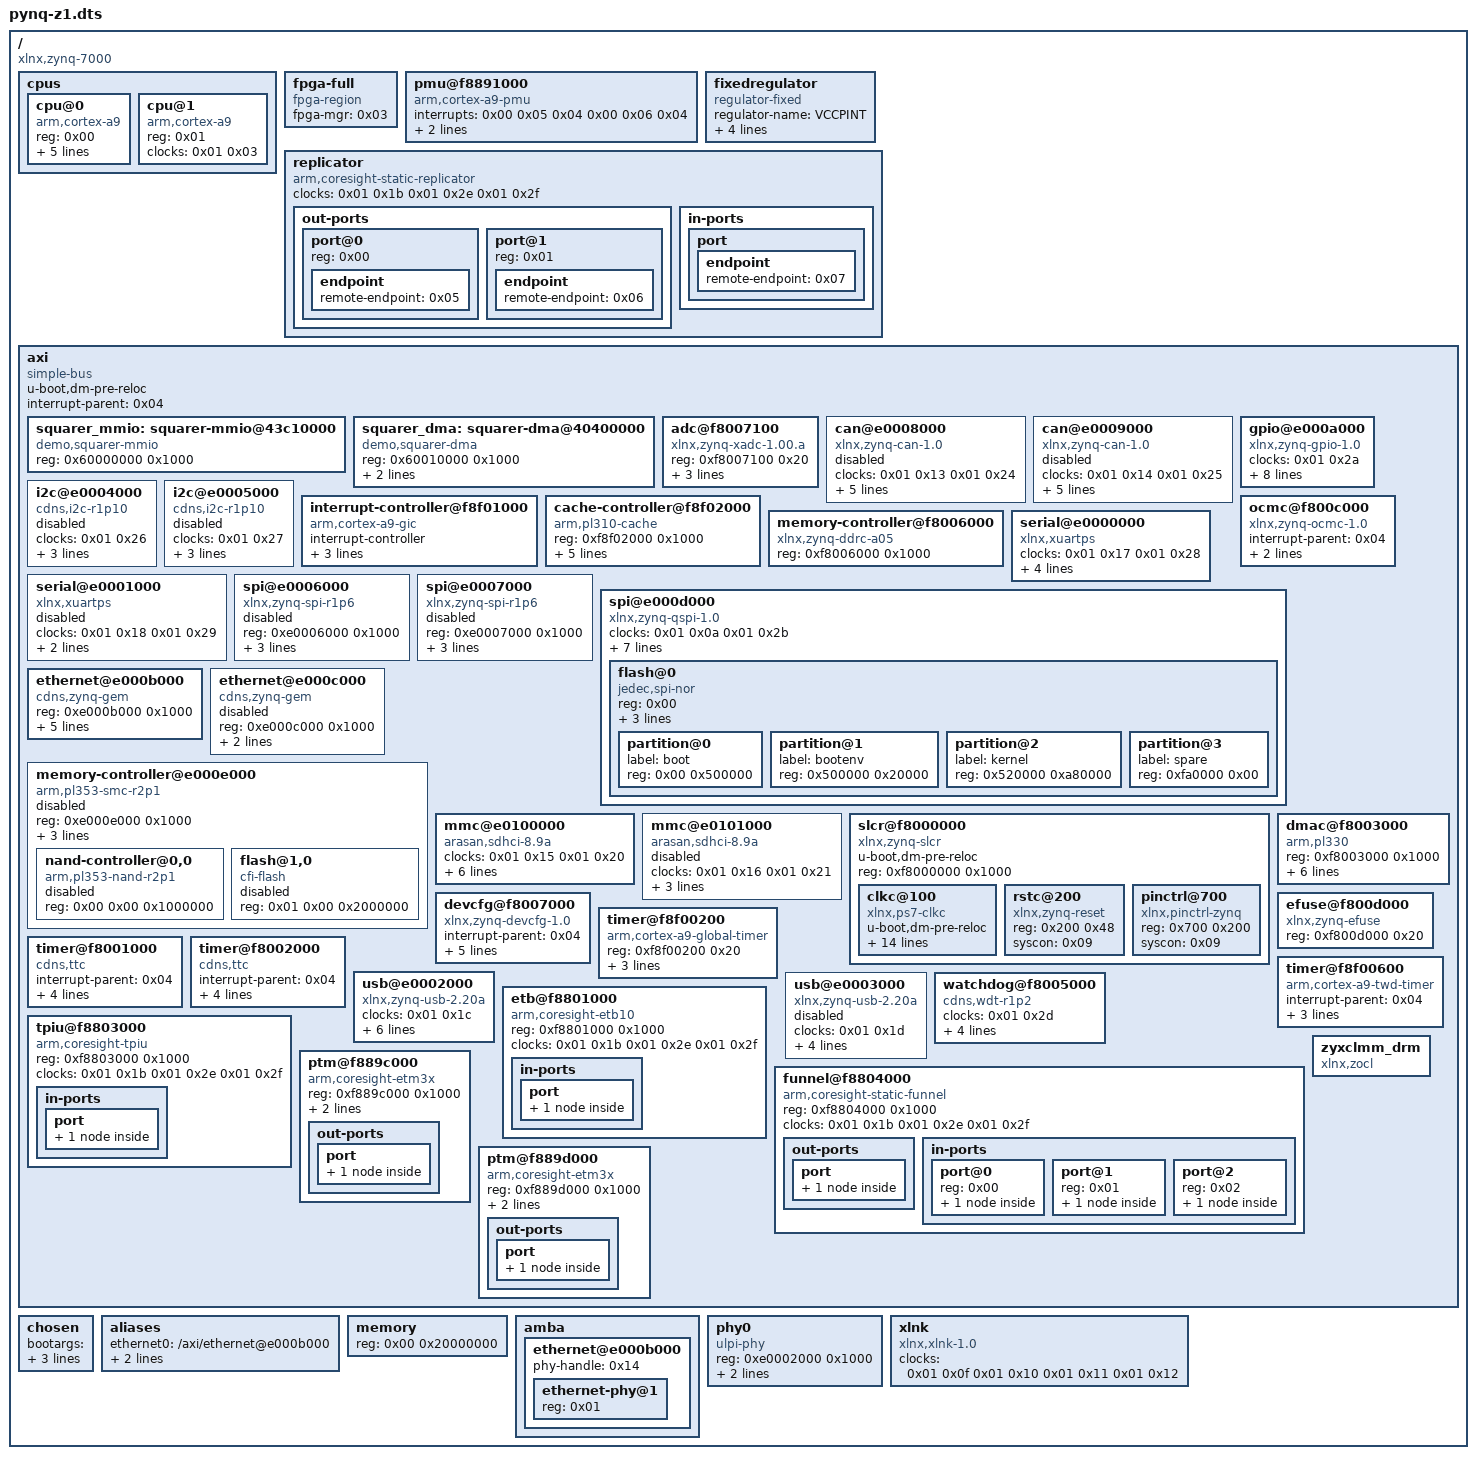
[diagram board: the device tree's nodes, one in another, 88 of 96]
/dts-v1/;

/ {
	#address-cells = <0x01>;
	#size-cells = <0x01>;
	compatible = "xlnx,zynq-7000";

	cpus {
		#address-cells = <0x01>;
		#size-cells = <0x00>;

		cpu@0 {
			compatible = "arm,cortex-a9";
			device_type = "cpu";
			reg = <0x00>;
			clocks = <0x01 0x03>;
			clock-latency = <0x3e8>;
			cpu0-supply = <0x02>;
			operating-points = <0x9eb10 0xf4240 0x4f588 0xf4240>;
			phandle = <0x10>;
		};

		cpu@1 {
			compatible = "arm,cortex-a9";
			device_type = "cpu";
			reg = <0x01>;
			clocks = <0x01 0x03>;
			phandle = <0x12>;
		};
	};

	fpga-full {
		compatible = "fpga-region";
		fpga-mgr = <0x03>;
		#address-cells = <0x01>;
		#size-cells = <0x01>;
		ranges;
		phandle = <0x15>;
	};

	pmu@f8891000 {
		compatible = "arm,cortex-a9-pmu";
		interrupts = <0x00 0x05 0x04 0x00 0x06 0x04>;
		interrupt-parent = <0x04>;
		reg = <0xf8891000 0x1000 0xf8893000 0x1000>;
	};

	fixedregulator {
		compatible = "regulator-fixed";
		regulator-name = "VCCPINT";
		regulator-min-microvolt = <0xf4240>;
		regulator-max-microvolt = <0xf4240>;
		regulator-boot-on;
		regulator-always-on;
		phandle = <0x02>;
	};

	replicator {
		compatible = "arm,coresight-static-replicator";
		clocks = <0x01 0x1b 0x01 0x2e 0x01 0x2f>;
		clock-names = "apb_pclk", "dbg_trc", "dbg_apb";

		out-ports {
			#address-cells = <0x01>;
			#size-cells = <0x00>;

			port@0 {
				reg = <0x00>;

				endpoint {
					remote-endpoint = <0x05>;
					phandle = <0x0c>;
				};
			};

			port@1 {
				reg = <0x01>;

				endpoint {
					remote-endpoint = <0x06>;
					phandle = <0x0b>;
				};
			};
		};

		in-ports {

			port {

				endpoint {
					remote-endpoint = <0x07>;
					phandle = <0x0d>;
				};
			};
		};
	};

	axi {
		u-boot,dm-pre-reloc;
		compatible = "simple-bus";
		#address-cells = <0x01>;
		#size-cells = <0x01>;
		interrupt-parent = <0x04>;
		ranges;
		phandle = <0x16>;

//        smarttimer0: smart-timer@70000000 {
//            compatible = "acme,smarttimer-v1";
//            reg = <0x70000000 0x10000>;
//            interrupts = <0 29 4>; // SPI 29 (on IRQ_F2P[0] of Zynq), level high
//            interrupt-parent = <0x04>;
//            status = "okay";
//        };

        // FIR filter with AXI DMA
        // reg[0] = FIR config registers (AXI-Lite)
        // reg[1] = AXI DMA registers
        // interrupts = S2MM completion IRQ
//        fir0: fir-filter@43c00000 {
//            compatible = "acme,fir-dma-v1";
//            reg = <0x43c00000 0x10000>,   // FIR config @ 0x43C0_0000
//                  <0x40400000 0x10000>;   // AXI DMA   @ 0x4040_0000
//            reg-names = "fir", "dma";
//            interrupts = <0 30 4>;        // SPI 30 (IRQ_F2P[1]), level high
//            interrupt-parent = <0x04>;
//            status = "disabled";          // Disable when using squarer demo
//        };

        // Squarer MMIO demo (slow path - per-sample register access)
        squarer_mmio: squarer-mmio@43c10000 {
            compatible = "demo,squarer-mmio";
            reg = <0x60000000 0x1000>;    // Squarer MMIO @ 0x6000_0000
            status = "okay";
        };

        // Squarer DMA demo (fast path - bulk transfer)
        // Uses AXI DMA for high-throughput data movement
        squarer_dma: squarer-dma@40400000 {
            compatible = "demo,squarer-dma";
            reg = <0x60010000 0x1000>;   // AXI DMA @ 0x6001_0000
            interrupts = <0 29 4>;        // SPI 29 (IRQ_F2P[0]), level high
            interrupt-parent = <0x04>;
            status = "okay";
        };

		adc@f8007100 {
			compatible = "xlnx,zynq-xadc-1.00.a";
			reg = <0xf8007100 0x20>;
			interrupts = <0x00 0x07 0x04>;
			interrupt-parent = <0x04>;
			clocks = <0x01 0x0c>;
			phandle = <0x17>;
		};

		can@e0008000 {
			compatible = "xlnx,zynq-can-1.0";
			status = "disabled";
			clocks = <0x01 0x13 0x01 0x24>;
			clock-names = "can_clk", "pclk";
			reg = <0xe0008000 0x1000>;
			interrupts = <0x00 0x1c 0x04>;
			interrupt-parent = <0x04>;
			tx-fifo-depth = <0x40>;
			rx-fifo-depth = <0x40>;
			phandle = <0x18>;
		};

		can@e0009000 {
			compatible = "xlnx,zynq-can-1.0";
			status = "disabled";
			clocks = <0x01 0x14 0x01 0x25>;
			clock-names = "can_clk", "pclk";
			reg = <0xe0009000 0x1000>;
			interrupts = <0x00 0x33 0x04>;
			interrupt-parent = <0x04>;
			tx-fifo-depth = <0x40>;
			rx-fifo-depth = <0x40>;
			phandle = <0x19>;
		};

		gpio@e000a000 {
			compatible = "xlnx,zynq-gpio-1.0";
			#gpio-cells = <0x02>;
			clocks = <0x01 0x2a>;
			gpio-controller;
			interrupt-controller;
			#interrupt-cells = <0x02>;
			interrupt-parent = <0x04>;
			interrupts = <0x00 0x14 0x04>;
			reg = <0xe000a000 0x1000>;
			emio-gpio-width = <0x40>;
			gpio-mask-high = <0x00>;
			gpio-mask-low = <0x5600>;
			phandle = <0x08>;
		};

		i2c@e0004000 {
			compatible = "cdns,i2c-r1p10";
			status = "disabled";
			clocks = <0x01 0x26>;
			interrupt-parent = <0x04>;
			interrupts = <0x00 0x19 0x04>;
			reg = <0xe0004000 0x1000>;
			#address-cells = <0x01>;
			#size-cells = <0x00>;
			phandle = <0x1a>;
		};

		i2c@e0005000 {
			compatible = "cdns,i2c-r1p10";
			status = "disabled";
			clocks = <0x01 0x27>;
			interrupt-parent = <0x04>;
			interrupts = <0x00 0x30 0x04>;
			reg = <0xe0005000 0x1000>;
			#address-cells = <0x01>;
			#size-cells = <0x00>;
			phandle = <0x1b>;
		};

		interrupt-controller@f8f01000 {
			compatible = "arm,cortex-a9-gic";
			#interrupt-cells = <0x03>;
			interrupt-controller;
			reg = <0xf8f01000 0x1000 0xf8f00100 0x100>;
			num_cpus = <0x02>;
			num_interrupts = <0x60>;
			phandle = <0x04>;
		};

		cache-controller@f8f02000 {
			compatible = "arm,pl310-cache";
			reg = <0xf8f02000 0x1000>;
			interrupts = <0x00 0x02 0x04>;
			arm,data-latency = <0x03 0x02 0x02>;
			arm,tag-latency = <0x02 0x02 0x02>;
			cache-unified;
			cache-level = <0x02>;
			phandle = <0x1c>;
		};

		memory-controller@f8006000 {
			compatible = "xlnx,zynq-ddrc-a05";
			reg = <0xf8006000 0x1000>;
			phandle = <0x1d>;
		};

		ocmc@f800c000 {
			compatible = "xlnx,zynq-ocmc-1.0";
			interrupt-parent = <0x04>;
			interrupts = <0x00 0x03 0x04>;
			reg = <0xf800c000 0x1000>;
			phandle = <0x1e>;
		};

		serial@e0000000 {
			compatible = "xlnx,xuartps", "cdns,uart-r1p8";
			status = "okay";
			clocks = <0x01 0x17 0x01 0x28>;
			clock-names = "uart_clk", "pclk";
			reg = <0xe0000000 0x1000>;
			interrupts = <0x00 0x1b 0x04>;
			cts-override;
			device_type = "serial";
			port-number = <0x00>;
			phandle = <0x1f>;
		};

		serial@e0001000 {
			compatible = "xlnx,xuartps", "cdns,uart-r1p8";
			status = "disabled";
			clocks = <0x01 0x18 0x01 0x29>;
			clock-names = "uart_clk", "pclk";
			reg = <0xe0001000 0x1000>;
			interrupts = <0x00 0x32 0x04>;
			phandle = <0x20>;
		};

		spi@e0006000 {
			compatible = "xlnx,zynq-spi-r1p6";
			reg = <0xe0006000 0x1000>;
			status = "disabled";
			interrupt-parent = <0x04>;
			interrupts = <0x00 0x1a 0x04>;
			clocks = <0x01 0x19 0x01 0x22>;
			clock-names = "ref_clk", "pclk";
			#address-cells = <0x01>;
			#size-cells = <0x00>;
			phandle = <0x21>;
		};

		spi@e0007000 {
			compatible = "xlnx,zynq-spi-r1p6";
			reg = <0xe0007000 0x1000>;
			status = "disabled";
			interrupt-parent = <0x04>;
			interrupts = <0x00 0x31 0x04>;
			clocks = <0x01 0x1a 0x01 0x23>;
			clock-names = "ref_clk", "pclk";
			#address-cells = <0x01>;
			#size-cells = <0x00>;
			phandle = <0x22>;
		};

		spi@e000d000 {
			clock-names = "ref_clk", "pclk";
			clocks = <0x01 0x0a 0x01 0x2b>;
			compatible = "xlnx,zynq-qspi-1.0";
			status = "okay";
			interrupt-parent = <0x04>;
			interrupts = <0x00 0x13 0x04>;
			reg = <0xe000d000 0x1000>;
			#address-cells = <0x01>;
			#size-cells = <0x00>;
			is-dual = <0x00>;
			num-cs = <0x01>;
			spi-rx-bus-width = <0x04>;
			spi-tx-bus-width = <0x04>;
			phandle = <0x23>;

			flash@0 {
				compatible = "jedec,spi-nor";
				reg = <0x00>;
				spi-tx-bus-width = <0x01>;
				spi-rx-bus-width = <0x04>;
				spi-max-frequency = <0x5f5e100>;
				phandle = <0x24>;

				partition@0 {
					label = "boot";
					reg = <0x00 0x500000>;
				};

				partition@1 {
					label = "bootenv";
					reg = <0x500000 0x20000>;
				};

				partition@2 {
					label = "kernel";
					reg = <0x520000 0xa80000>;
				};

				partition@3 {
					label = "spare";
					reg = <0xfa0000 0x00>;
				};
			};
		};

		ethernet@e000b000 {
			compatible = "cdns,zynq-gem", "cdns,gem";
			reg = <0xe000b000 0x1000>;
			status = "okay";
			interrupts = <0x00 0x16 0x04>;
			clocks = <0x01 0x1e 0x01 0x1e 0x01 0x0d>;
			clock-names = "pclk", "hclk", "tx_clk";
			#address-cells = <0x01>;
			#size-cells = <0x00>;
			enet-reset = <0x08 0x09 0x00>;
			phy-mode = "rgmii-id";
			xlnx,ptp-enet-clock = <0x6750918>;
			phandle = <0x25>;
		};

		ethernet@e000c000 {
			compatible = "cdns,zynq-gem", "cdns,gem";
			reg = <0xe000c000 0x1000>;
			status = "disabled";
			interrupts = <0x00 0x2d 0x04>;
			clocks = <0x01 0x1f 0x01 0x1f 0x01 0x0e>;
			clock-names = "pclk", "hclk", "tx_clk";
			#address-cells = <0x01>;
			#size-cells = <0x00>;
			phandle = <0x26>;
		};

		memory-controller@e000e000 {
			compatible = "arm,pl353-smc-r2p1", "arm,primecell";
			reg = <0xe000e000 0x1000>;
			status = "disabled";
			clock-names = "memclk", "apb_pclk";
			clocks = <0x01 0x0b 0x01 0x2c>;
			ranges = <0x00 0x00 0xe1000000 0x1000000 0x01 0x00 0xe2000000 0x2000000 0x02 0x00 0xe4000000 0x2000000>;
			#address-cells = <0x02>;
			#size-cells = <0x01>;
			interrupt-parent = <0x04>;
			interrupts = <0x00 0x12 0x04>;
			phandle = <0x27>;

			nand-controller@0,0 {
				compatible = "arm,pl353-nand-r2p1";
				reg = <0x00 0x00 0x1000000>;
				status = "disabled";
				#address-cells = <0x01>;
				#size-cells = <0x00>;
				phandle = <0x28>;
			};

			flash@1,0 {
				status = "disabled";
				compatible = "cfi-flash";
				reg = <0x01 0x00 0x2000000>;
				#address-cells = <0x01>;
				#size-cells = <0x01>;
				phandle = <0x29>;
			};
		};

		mmc@e0100000 {
			compatible = "arasan,sdhci-8.9a";
			status = "okay";
			clock-names = "clk_xin", "clk_ahb";
			clocks = <0x01 0x15 0x01 0x20>;
			interrupt-parent = <0x04>;
			interrupts = <0x00 0x18 0x04>;
			reg = <0xe0100000 0x1000>;
			xlnx,has-cd = <0x01>;
			xlnx,has-power = <0x00>;
			xlnx,has-wp = <0x00>;
			phandle = <0x2a>;
		};

		mmc@e0101000 {
			compatible = "arasan,sdhci-8.9a";
			status = "disabled";
			clock-names = "clk_xin", "clk_ahb";
			clocks = <0x01 0x16 0x01 0x21>;
			interrupt-parent = <0x04>;
			interrupts = <0x00 0x2f 0x04>;
			reg = <0xe0101000 0x1000>;
			phandle = <0x2b>;
		};

		slcr@f8000000 {
			u-boot,dm-pre-reloc;
			#address-cells = <0x01>;
			#size-cells = <0x01>;
			compatible = "xlnx,zynq-slcr", "syscon", "simple-mfd";
			reg = <0xf8000000 0x1000>;
			ranges;
			phandle = <0x09>;

			clkc@100 {
				u-boot,dm-pre-reloc;
				#clock-cells = <0x01>;
				compatible = "xlnx,ps7-clkc";
				fclk-enable = <0x0f>;
				clock-output-names = "armpll", "ddrpll", "iopll", "cpu_6or4x", "cpu_3or2x", "cpu_2x", "cpu_1x", "ddr2x", "ddr3x", "dci", "lqspi", "smc", "pcap", "gem0", "gem1", "fclk0", "fclk1", "fclk2", "fclk3", "can0", "can1", "sdio0", "sdio1", "uart0", "uart1", "spi0", "spi1", "dma", "usb0_aper", "usb1_aper", "gem0_aper", "gem1_aper", "sdio0_aper", "sdio1_aper", "spi0_aper", "spi1_aper", "can0_aper", "can1_aper", "i2c0_aper", "i2c1_aper", "uart0_aper", "uart1_aper", "gpio_aper", "lqspi_aper", "smc_aper", "swdt", "dbg_trc", "dbg_apb";
				reg = <0x100 0x100>;
				ps-clk-frequency = <0x2faf080>;
				phandle = <0x01>;
			};

			rstc@200 {
				compatible = "xlnx,zynq-reset";
				reg = <0x200 0x48>;
				#reset-cells = <0x01>;
				syscon = <0x09>;
				phandle = <0x2c>;
			};

			pinctrl@700 {
				compatible = "xlnx,pinctrl-zynq";
				reg = <0x700 0x200>;
				syscon = <0x09>;
				phandle = <0x2d>;
			};
		};

		dmac@f8003000 {
			compatible = "arm,pl330", "arm,primecell";
			reg = <0xf8003000 0x1000>;
			interrupt-parent = <0x04>;
			interrupt-names = "abort", "dma0", "dma1", "dma2", "dma3", "dma4", "dma5", "dma6", "dma7";
			interrupts = <0x00 0x0d 0x04 0x00 0x0e 0x04 0x00 0x0f 0x04 0x00 0x10 0x04 0x00 0x11 0x04 0x00 0x28 0x04 0x00 0x29 0x04 0x00 0x2a 0x04 0x00 0x2b 0x04>;
			#dma-cells = <0x01>;
			#dma-channels = <0x08>;
			#dma-requests = <0x04>;
			clocks = <0x01 0x1b>;
			clock-names = "apb_pclk";
			phandle = <0x2e>;
		};

		devcfg@f8007000 {
			compatible = "xlnx,zynq-devcfg-1.0";
			interrupt-parent = <0x04>;
			interrupts = <0x00 0x08 0x04>;
			reg = <0xf8007000 0x100>;
			clocks = <0x01 0x0c 0x01 0x0f 0x01 0x10 0x01 0x11 0x01 0x12>;
			clock-names = "ref_clk", "fclk0", "fclk1", "fclk2", "fclk3";
			syscon = <0x09>;
			phandle = <0x03>;
		};

		efuse@f800d000 {
			compatible = "xlnx,zynq-efuse";
			reg = <0xf800d000 0x20>;
			phandle = <0x2f>;
		};

		timer@f8f00200 {
			compatible = "arm,cortex-a9-global-timer";
			reg = <0xf8f00200 0x20>;
			interrupts = <0x01 0x0b 0x301>;
			interrupt-parent = <0x04>;
			clocks = <0x01 0x04>;
			phandle = <0x30>;
		};

		timer@f8001000 {
			interrupt-parent = <0x04>;
			interrupts = <0x00 0x0a 0x04 0x00 0x0b 0x04 0x00 0x0c 0x04>;
			compatible = "cdns,ttc";
			clocks = <0x01 0x06>;
			reg = <0xf8001000 0x1000>;
			phandle = <0x31>;
		};

		timer@f8002000 {
			interrupt-parent = <0x04>;
			interrupts = <0x00 0x25 0x04 0x00 0x26 0x04 0x00 0x27 0x04>;
			compatible = "cdns,ttc";
			clocks = <0x01 0x06>;
			reg = <0xf8002000 0x1000>;
			phandle = <0x32>;
		};

		timer@f8f00600 {
			interrupt-parent = <0x04>;
			interrupts = <0x01 0x0d 0x301>;
			compatible = "arm,cortex-a9-twd-timer";
			reg = <0xf8f00600 0x20>;
			clocks = <0x01 0x04>;
			phandle = <0x33>;
		};

		usb@e0002000 {
			compatible = "xlnx,zynq-usb-2.20a", "chipidea,usb2";
			status = "okay";
			clocks = <0x01 0x1c>;
			interrupt-parent = <0x04>;
			interrupts = <0x00 0x15 0x04>;
			reg = <0xe0002000 0x1000>;
			phy_type = "ulpi";
			usb-reset = <0x08 0x2e 0x00>;
			usb-phy = <0x0a>;
			phandle = <0x34>;
		};

		usb@e0003000 {
			compatible = "xlnx,zynq-usb-2.20a", "chipidea,usb2";
			status = "disabled";
			clocks = <0x01 0x1d>;
			interrupt-parent = <0x04>;
			interrupts = <0x00 0x2c 0x04>;
			reg = <0xe0003000 0x1000>;
			phy_type = "ulpi";
			phandle = <0x35>;
		};

		watchdog@f8005000 {
			clocks = <0x01 0x2d>;
			compatible = "cdns,wdt-r1p2";
			interrupt-parent = <0x04>;
			interrupts = <0x00 0x09 0x01>;
			reg = <0xf8005000 0x1000>;
			timeout-sec = <0x0a>;
			phandle = <0x36>;
		};

		etb@f8801000 {
			compatible = "arm,coresight-etb10", "arm,primecell";
			reg = <0xf8801000 0x1000>;
			clocks = <0x01 0x1b 0x01 0x2e 0x01 0x2f>;
			clock-names = "apb_pclk", "dbg_trc", "dbg_apb";

			in-ports {

				port {

					endpoint {
						remote-endpoint = <0x0b>;
						phandle = <0x06>;
					};
				};
			};
		};

		tpiu@f8803000 {
			compatible = "arm,coresight-tpiu", "arm,primecell";
			reg = <0xf8803000 0x1000>;
			clocks = <0x01 0x1b 0x01 0x2e 0x01 0x2f>;
			clock-names = "apb_pclk", "dbg_trc", "dbg_apb";

			in-ports {

				port {

					endpoint {
						remote-endpoint = <0x0c>;
						phandle = <0x05>;
					};
				};
			};
		};

		funnel@f8804000 {
			compatible = "arm,coresight-static-funnel", "arm,primecell";
			reg = <0xf8804000 0x1000>;
			clocks = <0x01 0x1b 0x01 0x2e 0x01 0x2f>;
			clock-names = "apb_pclk", "dbg_trc", "dbg_apb";

			out-ports {

				port {

					endpoint {
						remote-endpoint = <0x0d>;
						phandle = <0x07>;
					};
				};
			};

			in-ports {
				#address-cells = <0x01>;
				#size-cells = <0x00>;

				port@0 {
					reg = <0x00>;

					endpoint {
						remote-endpoint = <0x0e>;
						phandle = <0x11>;
					};
				};

				port@1 {
					reg = <0x01>;

					endpoint {
						remote-endpoint = <0x0f>;
						phandle = <0x13>;
					};
				};

				port@2 {
					reg = <0x02>;

					endpoint {
						phandle = <0x37>;
					};
				};
			};
		};

		ptm@f889c000 {
			compatible = "arm,coresight-etm3x", "arm,primecell";
			reg = <0xf889c000 0x1000>;
			clocks = <0x01 0x1b 0x01 0x2e 0x01 0x2f>;
			clock-names = "apb_pclk", "dbg_trc", "dbg_apb";
			cpu = <0x10>;

			out-ports {

				port {

					endpoint {
						remote-endpoint = <0x11>;
						phandle = <0x0e>;
					};
				};
			};
		};

		ptm@f889d000 {
			compatible = "arm,coresight-etm3x", "arm,primecell";
			reg = <0xf889d000 0x1000>;
			clocks = <0x01 0x1b 0x01 0x2e 0x01 0x2f>;
			clock-names = "apb_pclk", "dbg_trc", "dbg_apb";
			cpu = <0x12>;

			out-ports {

				port {

					endpoint {
						remote-endpoint = <0x13>;
						phandle = <0x0f>;
					};
				};
			};
		};

		zyxclmm_drm {
			compatible = "xlnx,zocl";
			status = "okay";
		};
	};

	chosen {
		bootargs = "root=/dev/mmcblk0p2 rw earlyprintk rootfstype=ext4 rootwait devtmpfs.mount=1 uio_pdrv_genirq.of_id=\"generic-uio\" clk_ignore_unused";
		stdout-path = "serial0:115200n8";
		pynq_board = "Pynq-Z1";
	};

	aliases {
		ethernet0 = "/axi/ethernet@e000b000";
		serial0 = "/axi/serial@e0000000";
		spi0 = "/axi/spi@e000d000";
	};

	memory {
		device_type = "memory";
		reg = <0x00 0x20000000>;
	};

	amba {

		ethernet@e000b000 {
			phy-handle = <0x14>;

			ethernet-phy@1 {
				reg = <0x01>;
				phandle = <0x14>;
			};
		};
	};

	phy0 {
		compatible = "ulpi-phy";
		#phy-cells = <0x00>;
		reg = <0xe0002000 0x1000>;
		view-port = <0x170>;
		drv-vbus;
		phandle = <0x0a>;
	};

	xlnk {
		compatible = "xlnx,xlnk-1.0";
		clock-names = "xclk0", "xclk1", "xclk2", "xclk3";
		clocks = <0x01 0x0f 0x01 0x10 0x01 0x11 0x01 0x12>;
	};

	// Below entry was from Pynq - comment out so we can use this interrupt
//	fabric@40000000 {
//		compatible = "generic-uio";
//		reg = <0x40000000 0x10000>;
//		interrupt-parent = <0x04>;
//		interrupts = <0x00 0x1d 0x04>;
//	};

	__symbols__ {
		cpu0 = "/cpus/cpu@0";
		cpu1 = "/cpus/cpu@1";
		fpga_full = "/fpga-full";
		regulator_vccpint = "/fixedregulator";
		replicator_out_port0 = "/replicator/out-ports/port@0/endpoint";
		replicator_out_port1 = "/replicator/out-ports/port@1/endpoint";
		replicator_in_port0 = "/replicator/in-ports/port/endpoint";
		amba = "/axi";
		adc = "/axi/adc@f8007100";
		can0 = "/axi/can@e0008000";
		can1 = "/axi/can@e0009000";
		gpio0 = "/axi/gpio@e000a000";
		i2c0 = "/axi/i2c@e0004000";
		i2c1 = "/axi/i2c@e0005000";
		intc = "/axi/interrupt-controller@f8f01000";
		L2 = "/axi/cache-controller@f8f02000";
		mc = "/axi/memory-controller@f8006000";
		ocmc = "/axi/ocmc@f800c000";
		uart0 = "/axi/serial@e0000000";
		uart1 = "/axi/serial@e0001000";
		spi0 = "/axi/spi@e0006000";
		spi1 = "/axi/spi@e0007000";
		qspi = "/axi/spi@e000d000";
		flash0 = "/axi/spi@e000d000/flash@0";
		gem0 = "/axi/ethernet@e000b000";
		gem1 = "/axi/ethernet@e000c000";
		smcc = "/axi/memory-controller@e000e000";
		nfc0 = "/axi/memory-controller@e000e000/nand-controller@0,0";
		nor0 = "/axi/memory-controller@e000e000/flash@1,0";
		sdhci0 = "/axi/mmc@e0100000";
		sdhci1 = "/axi/mmc@e0101000";
		slcr = "/axi/slcr@f8000000";
		clkc = "/axi/slcr@f8000000/clkc@100";
		rstc = "/axi/slcr@f8000000/rstc@200";
		pinctrl0 = "/axi/slcr@f8000000/pinctrl@700";
		dmac_s = "/axi/dmac@f8003000";
		devcfg = "/axi/devcfg@f8007000";
		efuse = "/axi/efuse@f800d000";
		global_timer = "/axi/timer@f8f00200";
		ttc0 = "/axi/timer@f8001000";
		ttc1 = "/axi/timer@f8002000";
		scutimer = "/axi/timer@f8f00600";
		usb0 = "/axi/usb@e0002000";
		usb1 = "/axi/usb@e0003000";
		watchdog0 = "/axi/watchdog@f8005000";
		etb_in_port = "/axi/etb@f8801000/in-ports/port/endpoint";
		tpiu_in_port = "/axi/tpiu@f8803000/in-ports/port/endpoint";
		funnel_out_port = "/axi/funnel@f8804000/out-ports/port/endpoint";
		funnel0_in_port0 = "/axi/funnel@f8804000/in-ports/port@0/endpoint";
		funnel0_in_port1 = "/axi/funnel@f8804000/in-ports/port@1/endpoint";
		funnel0_in_port2 = "/axi/funnel@f8804000/in-ports/port@2/endpoint";
		ptm0_out_port = "/axi/ptm@f889c000/out-ports/port/endpoint";
		ptm1_out_port = "/axi/ptm@f889d000/out-ports/port/endpoint";
		ethernet_phy = "/amba/ethernet@e000b000/ethernet-phy@1";
		usb_phy0 = "/phy0";
	};
};
